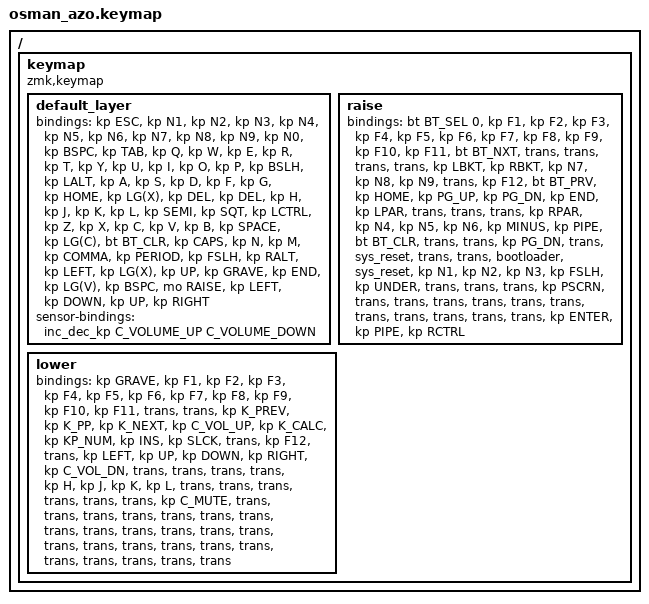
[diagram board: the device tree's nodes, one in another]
#include <behaviors.dtsi>
#include <dt-bindings/zmk/keys.h>
#include <dt-bindings/zmk/bt.h>
#include <dt-bindings/zmk/outputs.h>

#define DEFAULT 0
#define RAISE   1
#define LOWER   2

/ {
    keymap {
        compatible = "zmk,keymap";

        default_layer {
            bindings = <
&kp ESC    &kp N1   &kp N2  &kp N3   &kp N4 &kp N5                                                           &kp N6     &kp N7   &kp N8     &kp N9     &kp N0     &kp BSPC
&kp TAB    &kp Q    &kp W   &kp E    &kp R  &kp T                                                            &kp Y      &kp U    &kp I      &kp O      &kp P      &kp BSLH
&kp LALT   &kp A    &kp S   &kp D    &kp F  &kp G        &kp HOME   &kp LG(X)  &kp DEL    &kp DEL            &kp H      &kp J    &kp K      &kp L      &kp SEMI   &kp SQT
&kp LCTRL  &kp Z    &kp X   &kp C    &kp V  &kp B        &kp SPACE  &kp LG(C)  &bt BT_CLR &kp CAPS           &kp N      &kp M    &kp COMMA  &kp PERIOD &kp FSLH   &kp RALT
           &kp LEFT &kp LG(X) &kp UP &kp GRAVE    &kp END           &kp LG(V)  &kp BSPC           &mo RAISE             &kp LEFT &kp DOWN   &kp UP     &kp RIGHT
            >;
            sensor-bindings = <&inc_dec_kp C_VOLUME_UP C_VOLUME_DOWN>;
            };

        raise {
            bindings = <
&bt BT_SEL 0 &kp F1     &kp F2    &kp F3     &kp F4     &kp F5                                     &kp F6        &kp F7     &kp F8     &kp F9     &kp F10        &kp F11
&bt BT_NXT   &trans     &trans    &trans     &trans     &kp LBKT                                   &kp RBKT      &kp N7     &kp N8     &kp N9     &trans         &kp F12
&bt BT_PRV   &kp HOME   &kp PG_UP &kp PG_DN  &kp END    &kp LPAR   &trans     &trans    &trans     &kp RPAR      &kp N4     &kp N5     &kp N6     &kp MINUS      &kp PIPE
&bt BT_CLR   &trans     &trans    &kp PG_DN     &trans     &sys_reset &trans     &trans    &bootloader &sys_reset    &kp N1     &kp N2     &kp N3     &kp FSLH       &kp UNDER
&trans       &trans     &trans    &kp PSCRN  &trans     &trans     &trans     &trans    &trans     &trans        &trans     &trans     &trans     &trans         &trans
 &kp ENTER  &kp PIPE   &kp RCTRL
            >;
        };

        lower {
            bindings = <
&kp GRAVE  &kp F1     &kp F2     &kp F3     &kp F4     &kp F5                                     &kp F6     &kp F7     &kp F8     &kp F9     &kp F10     &kp F11
&trans     &trans     &kp K_PREV &kp K_PP   &kp K_NEXT &kp C_VOL_UP                               &kp K_CALC &kp KP_NUM &kp INS    &kp SLCK   &trans      &kp F12
&trans     &kp LEFT   &kp UP     &kp DOWN   &kp RIGHT  &kp C_VOL_DN &trans     &trans    &trans   &trans     &kp H      &kp J      &kp K      &kp L       &trans
&trans     &trans     &trans     &trans     &trans     &kp C_MUTE   &trans     &trans    &trans   &trans     &trans     &trans     &trans     &trans      &trans
&trans     &trans     &trans     &trans     &trans     &trans       &trans     &trans    &trans   &trans     &trans     &trans     &trans     &trans      &trans
            >;
        };
    };
};


